# ATtiny2313A device description
Architecture: AVR8; Family: tinyAVR
Registers are 8-bit, access not given, no defined reset value unless marked. A register's access mark holds for its fields unless they carry their own. Offsets are from the block's base; [hi:lo] are bit positions; {n}, {i} and the like mark numbered series; 'fields as' and 'values as' point back to an identical list.

## TC1 (TC16 module) — Timer/Counter, 16-bit
Instances: TC1 0x00
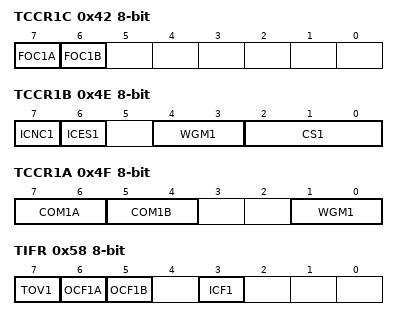
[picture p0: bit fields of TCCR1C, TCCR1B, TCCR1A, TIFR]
0x42 TCCR1C — Timer/Counter1 Control Register C
  [7] FOC1A — Force Output Compare for Channel A
  [6] FOC1B — Force Output Compare for Channel B
0x44 ICR1 16-bit — Timer/Counter1 Input Capture Register Bytes
0x48 OCR1B 16-bit — Timer/Counter1 Output Compare Register Bytes
0x4A OCR1A 16-bit — Timer/Counter1 Output Compare Register Bytes
0x4C TCNT1 16-bit — Timer/Counter1 Bytes
0x4E TCCR1B — Timer/Counter1 Control Register B
  [7] ICNC1 — Input Capture 1 Noise Canceler
  [6] ICES1 — Input Capture 1 Edge Select
  [4:3] WGM1 (bit 2 of the value upward) — Waveform Generation Mode Bits
  [2:0] CS1 — Clock Select1 bits
    0=NO_CLOCK_SOURCE_STOPPED; 1=RUNNING_NO_PRESCALING; 2=RUNNING_CLK_8; 3=RUNNING_CLK_64; 4=RUNNING_CLK_256; 5=RUNNING_CLK_1024; 6=RUNNING_EXTCLK_TN_FALLING_EDGE; 7=RUNNING_EXTCLK_TN_RISING_EDGE
0x4F TCCR1A — Timer/Counter1 Control Register A
  [7:6] COM1A — Compare Output Mode 1A, bits
  [5:4] COM1B — Compare Output Mode 1B, bits
  [1:0] WGM1 — Pulse Width Modulator Select Bits
0x58 TIFR — Timer/Counter Interrupt Flag register
  [7] TOV1 — Timer/Counter1 Overflow Flag
  [6] OCF1A — Output Compare Flag 1A
  [5] OCF1B — Output Compare Flag 1B
  [3] ICF1 — Input Capture Flag 1
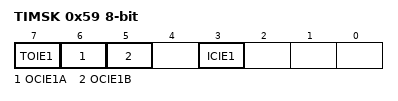
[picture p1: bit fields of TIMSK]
0x59 TIMSK — Timer/Counter Interrupt Mask Register
  [7] TOIE1 — Timer/Counter1 Overflow Interrupt Enable
  [6] OCIE1A — Timer/Counter1 Output CompareA Match Interrupt Enable
  [5] OCIE1B — Timer/Counter1 Output CompareB Match Interrupt Enable
  [3] ICIE1 — Timer/Counter1 Input Capture Interrupt Enable

## WDT — Watchdog Timer
Instances: WDT 0x00
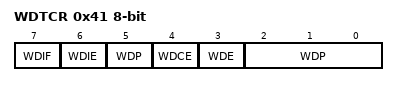
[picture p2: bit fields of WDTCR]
0x41 WDTCR — Watchdog Timer Control Register
  [7] WDIF — Watchdog Timeout Interrupt Flag
  [6] WDIE — Watchdog Timeout Interrupt Enable
  [4] WDCE — Watchdog Change Enable
  [3] WDE — Watch Dog Enable
  [5,2:0] WDP — Watchdog Timer Prescaler Bits
    0=OSCILLATOR_CYCLES_2K; 1=OSCILLATOR_CYCLES_4K; 2=OSCILLATOR_CYCLES_8K; 3=OSCILLATOR_CYCLES_16K; 4=OSCILLATOR_CYCLES_32K; 5=OSCILLATOR_CYCLES_64K; 6=OSCILLATOR_CYCLES_128K; 7=OSCILLATOR_CYCLES_256K; 8=OSCILLATOR_CYCLES_512K; 9=OSCILLATOR_CYCLES_1024K

## USART
Instances: USART 0x00
0x22 UBRRH bits used 3:0 — USART Baud Rate Register High Byte
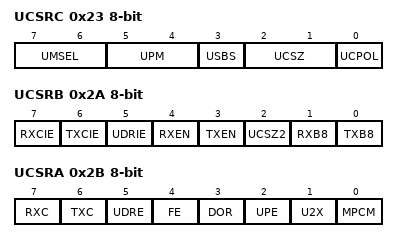
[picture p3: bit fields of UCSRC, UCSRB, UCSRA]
0x23 UCSRC — USART Control and Status Register C
  [7:6] UMSEL — USART Mode Select
    0=ASYNCHRONOUS_OPERATION; 1=SYNCHRONOUS_OPERATION; 3=MASTER_SPI
  [5:4] UPM — Parity Mode Bits
    0=DISABLED; 2=ENABLED_EVEN_PARITY; 3=ENABLED_ODD_PARITY
  [3] USBS — Stop Bit Select
    0=1_BIT; 1=2_BIT
  [2:1] UCSZ — Character Size Bits
  [0] UCPOL — Clock Polarity
0x29 UBRRL — USART Baud Rate Register Low Byte
0x2A UCSRB — USART Control and Status Register B
  [7] RXCIE — RX Complete Interrupt Enable
  [6] TXCIE — TX Complete Interrupt Enable
  [5] UDRIE — USART Data register Empty Interrupt Enable
  [4] RXEN — Receiver Enable
  [3] TXEN — Transmitter Enable
  [2] UCSZ2 — Character Size
  [1] RXB8 — Receive Data Bit 8
  [0] TXB8 — Transmit Data Bit 8
0x2B UCSRA — USART Control and Status Register A
  [7] RXC ro — USART Receive Complete
  [6] TXC — USART Transmit Complete
  [5] UDRE ro — USART Data Register Empty
  [4] FE ro — Framing Error
  [3] DOR ro — Data Overrun
  [2] UPE ro — USART Parity Error
  [1] U2X — Double the USART Transmission Speed
  [0] MPCM — Multi-processor Communication Mode
0x2C UDR — USART I/O Data Register

## AC — Analog Comparator
Instances: AC 0x00
0x21 DIDR bits used 1:0 — Digital Input Disable Register 1
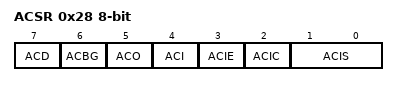
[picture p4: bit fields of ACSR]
0x28 ACSR — Analog Comparator Control And Status Register
  [7] ACD — Analog Comparator Disable
  [6] ACBG — Analog Comparator Bandgap Select
  [5] ACO — Analog Compare Output
  [4] ACI — Analog Comparator Interrupt Flag
  [3] ACIE — Analog Comparator Interrupt Enable
  [2] ACIC
  [1:0] ACIS — Analog Comparator Interrupt Mode Select bits
    0=INTERRUPT_ON_TOGGLE; 2=INTERRUPT_ON_FALLING_EDGE; 3=INTERRUPT_ON_RISING_EDGE

## EEPROM
Instances: EEPROM 0x00
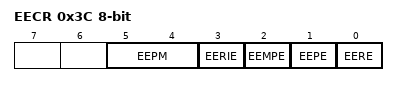
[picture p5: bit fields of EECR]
0x3C EECR — EEPROM Control Register
  [5:4] EEPM
    0=ERASE_AND_WRITE_IN_ONE_OPERATION; 1=ERASE_ONLY; 2=WRITE_ONLY
  [3] EERIE — EEProm Ready Interrupt Enable
  [2] EEMPE — EEPROM Master Write Enable
  [1] EEPE — EEPROM Write Enable
  [0] EERE — EEPROM Read Enable
0x3D EEDR — EEPROM Data Register
0x3E EEAR bits used 6:0 — EEPROM Read/Write Access

## USI — Universal Serial Interface
Instances: USI 0x00
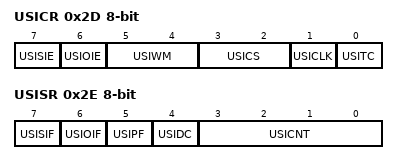
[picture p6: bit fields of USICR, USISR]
0x2D USICR — USI Control Register
  [7] USISIE — Start Condition Interrupt Enable
  [6] USIOIE — Counter Overflow Interrupt Enable
  [5:4] USIWM — USI Wire Mode Bits
    0=NORMAL_OPERATION; 1=THREE_WIRE_MODE; 2=TWO_WIRE_MODE; 3=TWO_WIRE_MODE_HELD_LOW
  [3:2] USICS — USI Clock Source Select Bits
  [1] USICLK — Clock Strobe
  [0] USITC — Toggle Clock Port Pin
0x2E USISR — USI Status Register
  [7] USISIF — Start Condition Interrupt Flag
  [6] USIOIF — Counter Overflow Interrupt Flag
  [5] USIPF — Stop Condition Flag
  [4] USIDC — Data Output Collision
  [3:0] USICNT — USI Counter Value Bits
0x2F USIDR — USI Data Register

## EXINT — External Interrupts
Instances: EXINT 0x00
0x24 PCMSK1 — Pin Change Interrupt Mask Register 1
  [2:0] PCINT (bit 8 of the value upward) — Pin Change Interrupt Masks
0x25 PCMSK2 — Pin Change Interrupt Mask Register 2
  [6:0] PCINT (bit 11 of the value upward) — Pin Change Interrupt Masks
0x40 PCMSK0 — Pin Change Interrupt Mask Register 0
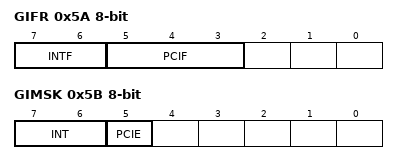
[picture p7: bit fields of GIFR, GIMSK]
0x5A GIFR — General Interrupt Flag Register
  [7:6] INTF — External Interrupt Flags
  [5:3] PCIF — Pin Change Interrupt Flags
0x5B GIMSK — General Interrupt Mask Register
  [7:6] INT — External Interrupt Request 1 Enable
  [5] PCIE

## CPU — CPU Registers
Instances: CPU 0x00
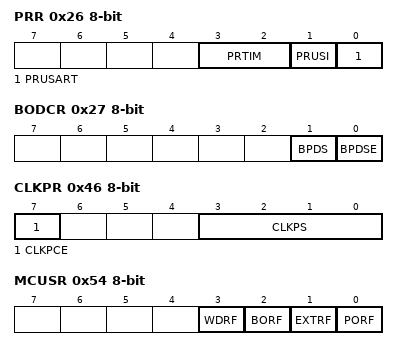
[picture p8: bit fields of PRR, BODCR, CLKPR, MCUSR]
0x26 PRR — Power reduction register
  [3:2] PRTIM, [1] PRUSI, [0] PRUSART
0x27 BODCR — BOD control register
  [1] BPDS, [0] BPDSE
{0x33+i} GPIOR{i} (i=0..2) — General Purpose I/O Register {i}
0x43 GTCCR — General Timer Counter Control Register
  [0] PSR10
0x46 CLKPR — Clock Prescale Register
  [7] CLKPCE — Clock Prescaler Change Enable
  [3:0] CLKPS — Clock Prescaler Select Bits
    0=1; 1=2; 2=4; 3=8; 4=16; 5=32; 6=64; 7=128; 8=256
0x51 OSCCAL — Oscillator Calibration Register
  [7:0] OSCCAL — Oscillator Calibration
0x54 MCUSR — MCU Status register
  [3] WDRF — Watchdog Reset Flag
  [2] BORF — Brown-out Reset Flag
  [1] EXTRF — External Reset Flag
  [0] PORF — Power-On Reset Flag
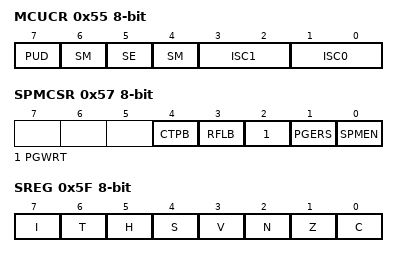
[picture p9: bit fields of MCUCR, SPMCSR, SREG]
0x55 MCUCR — MCU Control Register
  [7] PUD — Pull-up Disable
  [5] SE — Sleep Enable
  [6,4] SM — Sleep Mode Select Bits
    0=IDLE; 1=PDOWN2 (Power Down); 4=STDBY (Standby); 5=PDOWN (Power Down)
  [3:2] ISC1 — Interrupt Sense Control 1 bits
    0=LOW_LEVEL_OF_INTX; 1=ANY_LOGICAL_CHANGE_IN_INTX; 2=FALLING_EDGE_OF_INTX; 3=RISING_EDGE_OF_INTX
  [1:0] ISC0 — Interrupt Sense Control 0 bits
    values as ISC1
0x57 SPMCSR — Store Program Memory Control and Status register
  [4] CTPB — Clear Temporary Page Buffer
  [3] RFLB — Read Fuse and Lock Bits
  [2] PGWRT — Page Write
  [1] PGERS — Page Erase
  [0] SPMEN — Store Program Memory Enable
0x5D SPL — Stack Pointer Low Byte
0x5F SREG — Status Register
  [7] I — Global Interrupt Enable
  [6] T — Bit Copy Storage
  [5] H — Half Carry Flag
  [4] S — Sign Bit
  [3] V — Two's Complement Overflow Flag
  [2] N — Negative Flag
  [1] Z — Zero Flag
  [0] C — Carry Flag
Value list OSCCAL_VALUE_ADDRESSES: 0=8_MHz; 1=4_MHz
